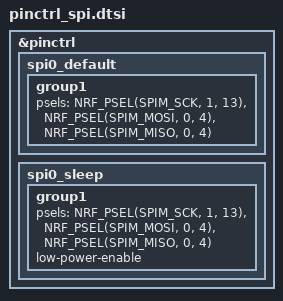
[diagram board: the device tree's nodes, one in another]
&pinctrl {
    spi0_default: spi0_default {
        group1 {
            psels = <NRF_PSEL(SPIM_SCK,  1, 13)>,
                    <NRF_PSEL(SPIM_MOSI, 0, 4)>,
                    <NRF_PSEL(SPIM_MISO, 0, 4)>;
        };
    };

    spi0_sleep: spi0_sleep {
        group1 {
            psels = <NRF_PSEL(SPIM_SCK,  1, 13)>,
                    <NRF_PSEL(SPIM_MOSI, 0, 4)>,
                    <NRF_PSEL(SPIM_MISO, 0, 4)>;
            low-power-enable;
        };
    };
};

// &spi0 {
//     status = "okay";
//     cs-gpios =  <&xiao_d 7 GPIO_ACTIVE_LOW>;
//     pinctrl-0 = <&spi0_default>;
//     pinctrl-1 = <&spi0_sleep>;
//     pinctrl-names = "default", "sleep";
//     compatible = "nordic,nrf-spim";
// };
